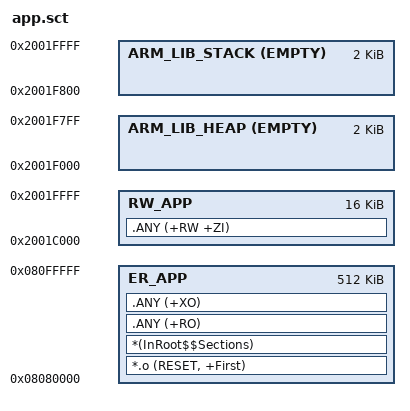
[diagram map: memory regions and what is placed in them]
; *************************************************************
; ***  本文件由 tools/gen_scatter.py 自动生成，请勿手工编辑  ***
; ***  配置源头: config/svcrt_partition.h                    ***
; ***  修改布局请改配置头，然后重新编译（编译前会自动重新生成） ***
; *************************************************************

LR_APP 0x08080000 0x00080000  {
  ER_APP 0x08080000 0x00080000  {
   *.o (RESET, +First)          ; 启动入口向量表必须位于分区首地址
   *(InRoot$$Sections)
   .ANY (+RO)
   .ANY (+XO)
  }
  RW_APP 0x2001C000 0x00004000  {
   .ANY (+RW +ZI)
  }
  ARM_LIB_STACK 0x20020000 EMPTY -0x800 {   ; 栈 2048 字节（高地址，向下生长）
  }
  ARM_LIB_HEAP  0x2001F000 EMPTY  0x800 {   ; 堆 2048 字节
  }
}
